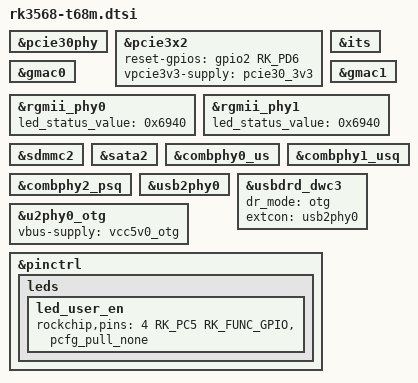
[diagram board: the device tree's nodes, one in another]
// SPDX-License-Identifier: (GPL-2.0+ OR MIT)
/*
* Copyright (c) 2020 Rockchip Electronics Co., Ltd.
*
*/

#include "rk3568-t68m-port.dtsi"

&pcie30phy {
	status = "okay";
};

&pcie3x2 {
	reset-gpios = <&gpio2 RK_PD6 GPIO_ACTIVE_HIGH>;
	vpcie3v3-supply = <&pcie30_3v3>;

	status = "okay";
};

&its {
	status = "okay";
};

&gmac0 {
	status = "okay";
};

&gmac1 {
	status = "okay";
};

&rgmii_phy0 {
	led_status_value = <0x6940>;
};

&rgmii_phy1 {
	led_status_value = <0x6940>;
};

&sdmmc2 {
	status = "okay";
};

&sata2 {
	status = "okay";
};

&combphy0_us {
	status = "okay";
};

&combphy1_usq {
	status = "okay";
};

&combphy2_psq {
	status = "okay";
};

&usb2phy0 {
	status = "okay";
};

&usbdrd_dwc3 {
	dr_mode = "otg";
	extcon = <&usb2phy0>;
	status = "okay";
};

&u2phy0_otg {
	vbus-supply = <&vcc5v0_otg>;
	status = "okay";
};

&pinctrl {
	leds {
		led_user_en: led_user_en {
			rockchip,pins = <4 RK_PC5 RK_FUNC_GPIO &pcfg_pull_none>;
		};
	};
};
